LIN_description_file;
LIN_protocol_version = "2.1";
LIN_language_version = "2.1";
LIN_speed = 19.2 kbps;

Nodes {
  Master: LIN_Commander, 1 ms, 0 ms ;
  Slaves: CONTROL_BOX ;
}

Signals {
  Enables_0x00_test1: 8, 0, LIN_Commander, CONTROL_BOX ;
  Enables_0x00_test2: 8, 0, LIN_Commander, CONTROL_BOX ;
  Enables_0x00_test3: 8, 0, LIN_Commander, CONTROL_BOX ;
  Enables_0x00_test4: 8, 0, LIN_Commander, CONTROL_BOX ;
  ADC_0x01_voltage: 8, 0, CONTROL_BOX, LIN_Commander ;
  ADC_0x01_temper: 8, 0, CONTROL_BOX, LIN_Commander ;
}

Frames {
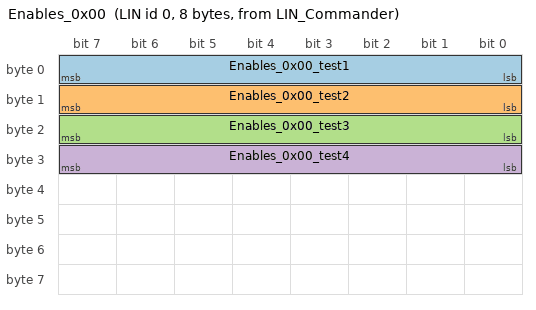
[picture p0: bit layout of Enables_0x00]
  Enables_0x00: 0, LIN_Commander, 8 {
    Enables_0x00_test1, 0 ;
    Enables_0x00_test2, 8 ;
    Enables_0x00_test3, 16 ;
    Enables_0x00_test4, 24 ;
  }
  ADC_0x01: 1, CONTROL_BOX, 8 {
    ADC_0x01_voltage, 0 ;
    ADC_0x01_temper, 8 ;
  }
}

Node_attributes {
  CONTROL_BOX{
    LIN_protocol = "2.1" ;
    configured_NAD = 0xFF ;
    initial_NAD = 0xFF ;
    product_id = 0x0, 0x0, 255 ;
    P2_min = 50 ms ;
    ST_min = 0 ms ;
    N_As_timeout = 1000 ms ;
    N_Cr_timeout = 1000 ms ;
    configurable_frames {
      Enables_0x00 ;
      ADC_0x01 ;
    }
  }
}

Schedule_tables {
}
